VERSION ""

NS_ :

BS_:

BU_: ORION

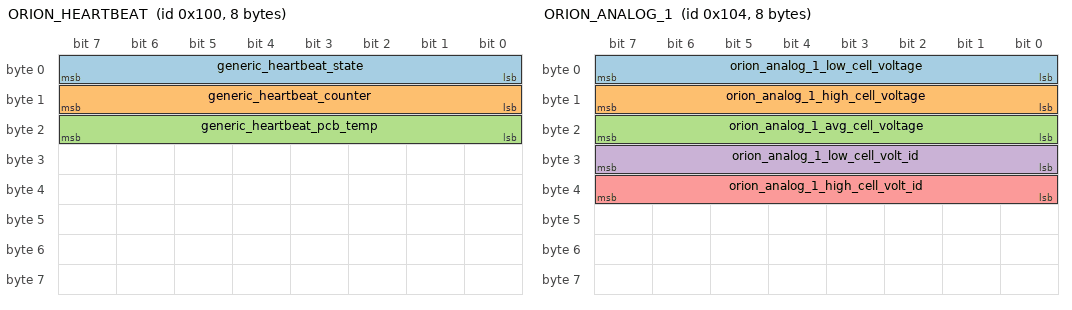
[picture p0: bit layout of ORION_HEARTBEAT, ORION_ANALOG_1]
BO_ 256 ORION_HEARTBEAT: 8 ORION
 SG_ generic_heartbeat_state : 0|8@1+ (1,0) [0|0] "" Vector__XXX
 SG_ generic_heartbeat_counter : 8|8@1+ (1,0) [0|0] "" Vector__XXX
 SG_ generic_heartbeat_pcb_temp : 16|8@1+ (1,0) [0|0] "" Vector__XXX

BO_ 260 ORION_ANALOG_1: 8 ORION
 SG_ orion_analog_1_low_cell_voltage : 0|8@1+ (1,0) [0|0] "" Vector__XXX
 SG_ orion_analog_1_high_cell_voltage : 8|8@1+ (1,0) [0|0] "" Vector__XXX
 SG_ orion_analog_1_avg_cell_voltage : 16|8@1+ (1,0) [0|0] "" Vector__XXX
 SG_ orion_analog_1_low_cell_volt_id : 24|8@1+ (1,0) [0|0] "" Vector__XXX
 SG_ orion_analog_1_high_cell_volt_id : 32|8@1+ (1,0) [0|0] "" Vector__XXX

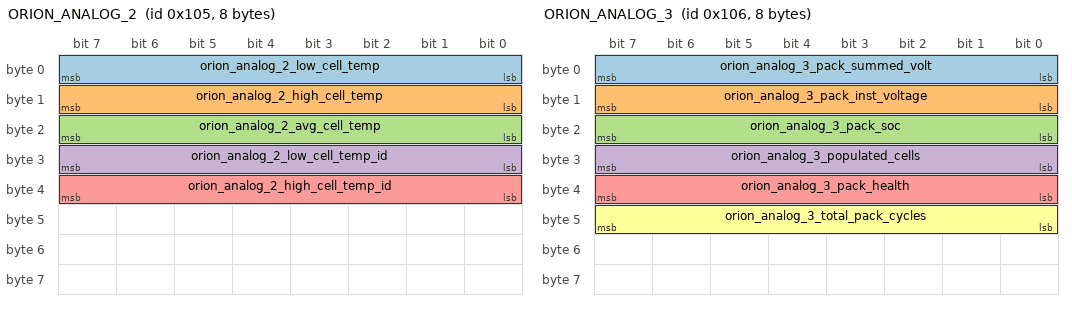
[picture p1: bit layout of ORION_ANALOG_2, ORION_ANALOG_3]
BO_ 261 ORION_ANALOG_2: 8 ORION
 SG_ orion_analog_2_low_cell_temp : 0|8@1+ (1,0) [0|0] "" Vector__XXX
 SG_ orion_analog_2_high_cell_temp : 8|8@1+ (1,0) [0|0] "" Vector__XXX
 SG_ orion_analog_2_avg_cell_temp : 16|8@1+ (1,0) [0|0] "" Vector__XXX
 SG_ orion_analog_2_low_cell_temp_id : 24|8@1+ (1,0) [0|0] "" Vector__XXX
 SG_ orion_analog_2_high_cell_temp_id : 32|8@1+ (1,0) [0|0] "" Vector__XXX

BO_ 262 ORION_ANALOG_3: 8 ORION
 SG_ orion_analog_3_pack_summed_volt : 0|8@1+ (1,0) [0|0] "" Vector__XXX
 SG_ orion_analog_3_pack_inst_voltage : 8|8@1+ (1,0) [0|0] "" Vector__XXX
 SG_ orion_analog_3_pack_soc : 16|8@1+ (1,0) [0|0] "" Vector__XXX
 SG_ orion_analog_3_populated_cells : 24|8@1+ (1,0) [0|0] "" Vector__XXX
 SG_ orion_analog_3_pack_health : 32|8@1+ (1,0) [0|0] "" Vector__XXX
 SG_ orion_analog_3_total_pack_cycles : 40|8@1+ (1,0) [0|0] "" Vector__XXX

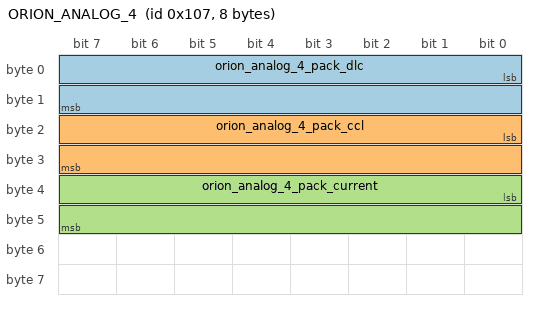
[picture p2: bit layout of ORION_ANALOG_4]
BO_ 263 ORION_ANALOG_4: 8 ORION
 SG_ orion_analog_4_pack_dlc : 0|16@1+ (1,0) [0|0] "" Vector__XXX
 SG_ orion_analog_4_pack_ccl : 16|16@1+ (1,0) [0|0] "" Vector__XXX
 SG_ orion_analog_4_pack_current : 32|16@1+ (1,0) [0|0] "" Vector__XXX

BO_ 258 ORION_ERROR_WARNING: 8 ORION
 SG_ orion_dtc_status_1 : 0|16@1+ (1,0) [0|0] "" Vector__XXX
 SG_ orion_dtc_status_2 : 16|16@1+ (1,0) [0|0] "" Vector__XXX

BA_DEF_  "BusType" STRING ;
BA_DEF_DEF_  "BusType" "CAN";
